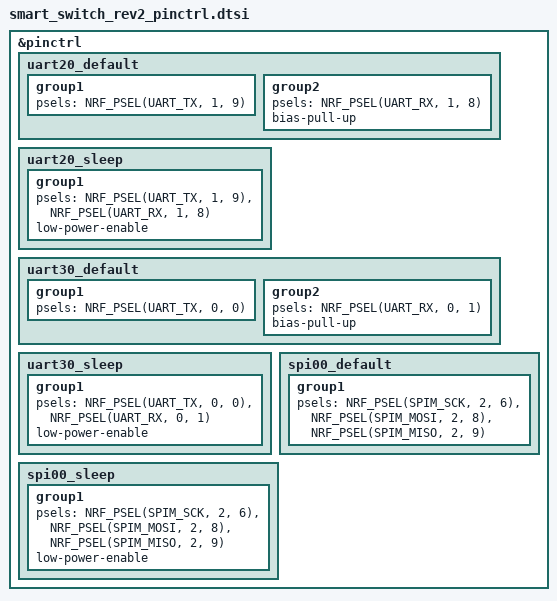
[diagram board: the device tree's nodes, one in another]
/*
 * Copyright (c) 2024 Nordic Semiconductor
 * SPDX-License-Identifier: Apache-2.0
 *
 * smart_switch_rev2 (u-blox NORA-B206 / nRF54L15) pin assignments.
 */

&pinctrl {
	/* Debug console, routed to the TC2050 connector (J4 pin 5 = TX, pin 6 = RX).
	 * Port 1 pins, so this must be a UARTE2x instance (UARTE00 is port-2 only).
	 */
	/omit-if-no-ref/ uart20_default: uart20_default {
		group1 {
			psels = <NRF_PSEL(UART_TX, 1, 9)>;
		};

		group2 {
			psels = <NRF_PSEL(UART_RX, 1, 8)>;
			bias-pull-up;
		};
	};

	/omit-if-no-ref/ uart20_sleep: uart20_sleep {
		group1 {
			psels = <NRF_PSEL(UART_TX, 1, 9)>,
				<NRF_PSEL(UART_RX, 1, 8)>;
			low-power-enable;
		};
	};

	/* UARTE30: left disabled by the app; TF-M's secure UART in the /ns build.
	 * P0.00 / P0.01 are test points TP2 / TP1 on rev2.
	 */
	/omit-if-no-ref/ uart30_default: uart30_default {
		group1 {
			psels = <NRF_PSEL(UART_TX, 0, 0)>;
		};

		group2 {
			psels = <NRF_PSEL(UART_RX, 0, 1)>;
			bias-pull-up;
		};
	};

	/omit-if-no-ref/ uart30_sleep: uart30_sleep {
		group1 {
			psels = <NRF_PSEL(UART_TX, 0, 0)>,
				<NRF_PSEL(UART_RX, 0, 1)>;
			low-power-enable;
		};
	};

	/* External SPI NOR flash (U2, W25Q32JV). CS (P2.05) is driven via cs-gpios.
	 * NOTE: SCK on P2.06 - verify against the nRF54L15 datasheet's dedicated
	 * clock-pin table for SPIM00; Nordic's own boards all use P2.01 for SCK.
	 */
	/omit-if-no-ref/ spi00_default: spi00_default {
		group1 {
			psels = <NRF_PSEL(SPIM_SCK, 2, 6)>,
				<NRF_PSEL(SPIM_MOSI, 2, 8)>,
				<NRF_PSEL(SPIM_MISO, 2, 9)>;
		};
	};

	/omit-if-no-ref/ spi00_sleep: spi00_sleep {
		group1 {
			psels = <NRF_PSEL(SPIM_SCK, 2, 6)>,
				<NRF_PSEL(SPIM_MOSI, 2, 8)>,
				<NRF_PSEL(SPIM_MISO, 2, 9)>;
			low-power-enable;
		};
	};
};
